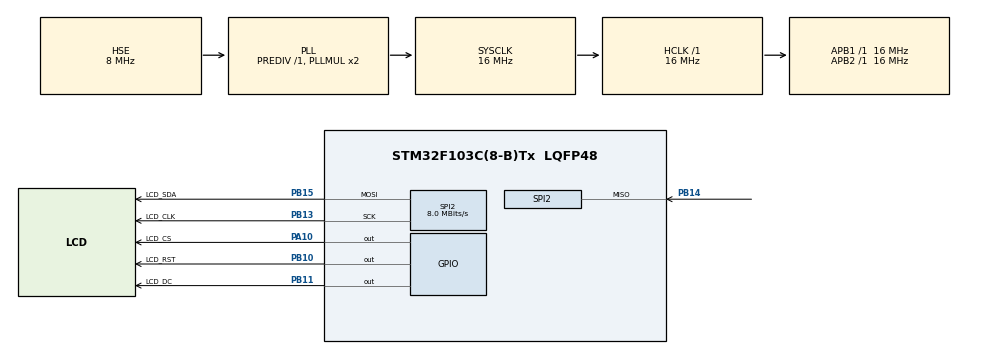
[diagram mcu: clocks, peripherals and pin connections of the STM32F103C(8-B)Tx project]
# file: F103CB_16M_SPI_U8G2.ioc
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Mcu.Family=STM32F1
Mcu.Name=STM32F103C(8-B)Tx
Mcu.Package=LQFP48
NVIC.PriorityGroup=NVIC_PRIORITYGROUP_4
PA10.GPIO_Label=LCD_CS
PA10.Signal=GPIO_Output
PA13.Mode=Serial_Wire
PA13.Signal=SYS_JTMS-SWDIO
PA14.Mode=Serial_Wire
PA14.Signal=SYS_JTCK-SWCLK
PB10.GPIO_Label=LCD_RST
PB10.Signal=GPIO_Output
PB11.GPIO_Label=LCD_DC
PB11.Signal=GPIO_Output
PB13.GPIO_Label=LCD_CLK
PB13.Mode=Full_Duplex_Master
PB13.Signal=SPI2_SCK
PB14.Mode=Full_Duplex_Master
PB14.Signal=SPI2_MISO
PB15.GPIO_Label=LCD_SDA
PB15.Mode=Full_Duplex_Master
PB15.Signal=SPI2_MOSI
PD0-OSC_IN.Mode=HSE-External-Oscillator
PD0-OSC_IN.Signal=RCC_OSC_IN
PD1-OSC_OUT.Mode=HSE-External-Oscillator
PD1-OSC_OUT.Signal=RCC_OSC_OUT
ProjectManager.HeapSize=0x200
ProjectManager.StackSize=0x400
ProjectManager.TargetToolchain=MDK-ARM V5.32
RCC.AHBFreq_Value=16000000
RCC.APB1Freq_Value=16000000
RCC.APB1TimFreq_Value=16000000
RCC.APB2Freq_Value=16000000
RCC.APB2TimFreq_Value=16000000
RCC.HCLKFreq_Value=16000000
RCC.PLLSourceVirtual=RCC_PLLSOURCE_HSE
RCC.SYSCLKFreq_VALUE=16000000
RCC.SYSCLKSource=RCC_SYSCLKSOURCE_PLLCLK
RCC.USBFreq_Value=16000000
SPI2.CalculateBaudRate=8.0 MBits/s
SPI2.Direction=SPI_DIRECTION_2LINES
SPI2.Mode=SPI_MODE_MASTER
SPI2.VirtualType=VM_MASTER
board=custom

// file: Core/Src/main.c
/* USER CODE BEGIN Header */
/**
 ******************************************************************************
 * @file           : main.c
 * @brief          : Main program body
 ******************************************************************************
 * @attention
 *
 * Copyright (c) 2025 STMicroelectronics.
 * All rights reserved.
 *
 * This software is licensed under terms that can be found in the LICENSE file
 * in the root directory of this software component.
 * If no LICENSE file comes with this software, it is provided AS-IS.
 *
 ******************************************************************************
 */
/* USER CODE END Header */
#include "gpio.h"
#include "main.h"
#include "spi.h"

/* USER CODE BEGIN Includes */

#include "u8g2.h"

#include "lcd.h"

/* USER CODE END Includes */

void SystemClock_Config(void);

/* USER CODE BEGIN 0 */
uint64_t mainRunCount = 0;

// void draw(u8g2_t *u8g2)
//{
//     u8g2_SetFont(u8g2, u8g2_font_6x12_tf);  //????
//     u8g2_DrawStr(u8g2, 80,36,"WWWWW");    //????
//     u8g2_SetFontMode(u8g2, 1); /*??????*/
//     u8g2_SetFontDirection(u8g2, 0); /*??????*/
//     u8g2_SetFont(u8g2, u8g2_font_inb24_mf); /*????*/
//     u8g2_DrawStr(u8g2, 0, 20, "U");
//
//     u8g2_SetFontDirection(u8g2, 1);
//     u8g2_SetFont(u8g2, u8g2_font_inb30_mn);
//     u8g2_DrawStr(u8g2, 21,8,"8");
//
//     u8g2_SetFontDirection(u8g2, 0);
//     u8g2_SetFont(u8g2, u8g2_font_inb24_mf);
//     u8g2_DrawStr(u8g2, 51,30,"g");
//     u8g2_DrawStr(u8g2, 67,30,"\xb2");
//
//     u8g2_DrawHLine(u8g2, 2, 35, 47);
//     u8g2_DrawHLine(u8g2, 3, 36, 47);
//     u8g2_DrawVLine(u8g2, 45, 32, 12);
//     u8g2_DrawVLine(u8g2, 46, 33, 12);
//
//     u8g2_SetFont(u8g2, u8g2_font_4x6_tr);
//     u8g2_DrawStr(u8g2, 1,54,"github.com/olikraus/u8g2");
//	}

/* USER CODE END 0 */

int main(void) {

  /* MCU Configuration--------------------------------------------------------*/

  /* Reset of all peripherals, Initializes the Flash interface and the Systick.
   */
  HAL_Init();

  /* Configure the system clock */
  SystemClock_Config();

  /* Initialize all configured peripherals */
  MX_GPIO_Init();
  MX_SPI2_Init();
  /* USER CODE BEGIN 2 */

  u8g2_t u8g2;     // ?????????
  u8g2Init(&u8g2); //??????????

  u8g2_ClearBuffer(&u8g2);
  u8g2_SetFont(&u8g2, u8g2_font_ncenB14_tr);
  u8g2_DrawStr(&u8g2, 0, 20, "Hello World!");
  u8g2_SendBuffer(&u8g2);

  // u8g2_DrawStr(&u8g2, 2, 60, "Hello World!");

  /* USER CODE END 2 */

  /* Infinite loop */
  while (1) {

    /* USER CODE BEGIN 3 */

    //		  u8g2_FirstPage(&u8g2);
    //       do
    //       {
    //   			draw(&u8g2);
    //
    //       } while (u8g2_NextPage(&u8g2));

    mainRunCount++;
    HAL_Delay(1000);
  }
  /* USER CODE END 3 */
}

void SystemClock_Config(void) {
  RCC_OscInitTypeDef RCC_OscInitStruct = {0};
  RCC_ClkInitTypeDef RCC_ClkInitStruct = {0};

  /** Initializes the RCC Oscillators according to the specified parameters
   * in the RCC_OscInitTypeDef structure.
   */
  RCC_OscInitStruct.OscillatorType = RCC_OSCILLATORTYPE_HSE;
  RCC_OscInitStruct.HSEState = RCC_HSE_ON;
  RCC_OscInitStruct.HSEPredivValue = RCC_HSE_PREDIV_DIV1;
  RCC_OscInitStruct.HSIState = RCC_HSI_ON;
  RCC_OscInitStruct.PLL.PLLState = RCC_PLL_ON;
  RCC_OscInitStruct.PLL.PLLSource = RCC_PLLSOURCE_HSE;
  RCC_OscInitStruct.PLL.PLLMUL = RCC_PLL_MUL2;
  if (HAL_RCC_OscConfig(&RCC_OscInitStruct) != HAL_OK) {
    Error_Handler();
  }

  /** Initializes the CPU, AHB and APB buses clocks
   */
  RCC_ClkInitStruct.ClockType = RCC_CLOCKTYPE_HCLK | RCC_CLOCKTYPE_SYSCLK |
                                RCC_CLOCKTYPE_PCLK1 | RCC_CLOCKTYPE_PCLK2;
  RCC_ClkInitStruct.SYSCLKSource = RCC_SYSCLKSOURCE_PLLCLK;
  RCC_ClkInitStruct.AHBCLKDivider = RCC_SYSCLK_DIV1;
  RCC_ClkInitStruct.APB1CLKDivider = RCC_HCLK_DIV1;
  RCC_ClkInitStruct.APB2CLKDivider = RCC_HCLK_DIV1;

  if (HAL_RCC_ClockConfig(&RCC_ClkInitStruct, FLASH_LATENCY_0) != HAL_OK) {
    Error_Handler();
  }
}

void Error_Handler(void) {
  __disable_irq();
  while (1) {
  }
}

#ifdef USE_FULL_ASSERT
/**
 * @brief  Reports the name of the source file and the source line number
 *         where the assert_param error has occurred.
 * @param  file: pointer to the source file name
 * @param  line: assert_param error line source number
 * @retval None
 */
void assert_failed(uint8_t *file, uint32_t line) {
  /* USER CODE BEGIN 6 */
  /* User can add his own implementation to report the file name and line
     number, ex: printf("Wrong parameters value: file %s on line %d\r\n", file,
     line) */
  /* USER CODE END 6 */
}
#endif /* USE_FULL_ASSERT */
